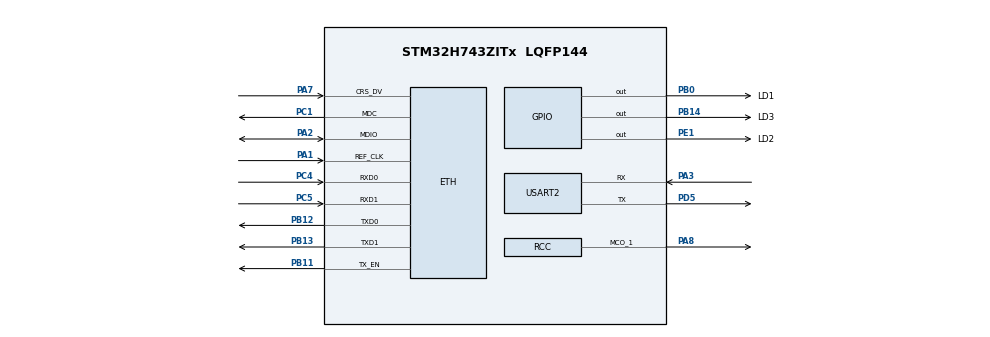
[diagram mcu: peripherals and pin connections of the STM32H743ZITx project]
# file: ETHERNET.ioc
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CORTEX_M7.CPU_DCache=Enabled
CORTEX_M7.CPU_ICache=Enabled
ETH.MediaInterface=HAL_ETH_RMII_MODE
LWIP.BSP.number=1
LWIP.GATEWAY_ADDRESS=192.168.001.001
LWIP.IP_ADDRESS=192.168.001.123
LWIP.LWIP_DHCP=0
LWIP.NETMASK_ADDRESS=255.255.255.000
LWIP.Version=v2.0.3_Cube
LWIP0.BSP.STBoard=false
LWIP0.BSP.api=BSP_COMPONENT_DRIVER
LWIP0.BSP.component=LAN8742
LWIP0.BSP.i2caddr=0
LWIP0.BSP.instance=LAN8742
LWIP0.BSP.name=Driver_PHY
LWIP0.BSP.solution=LAN8742
Mcu.Family=STM32H7
Mcu.Name=STM32H743ZITx
Mcu.Package=LQFP144
NVIC.ETH_IRQn=true\:0\:0\:false\:false\:true\:true\:true
NVIC.PriorityGroup=NVIC_PRIORITYGROUP_4
PA1.Mode=RMII
PA1.Signal=ETH_REF_CLK
PA2.Mode=RMII
PA2.Signal=ETH_MDIO
PA3.Mode=Asynchronous
PA3.Signal=USART2_RX
PA7.Mode=RMII
PA7.Signal=ETH_CRS_DV
PA8.Mode=Clock-out-1
PA8.Signal=RCC_MCO_1
PB0.GPIO_Label=LD1
PB0.GPIO_ModeDefaultOutputPP=GPIO_MODE_OUTPUT_PP
PB0.GPIO_PuPd=GPIO_NOPULL
PB0.GPIO_Speed=GPIO_SPEED_FREQ_VERY_HIGH
PB0.PinState=GPIO_PIN_RESET
PB0.Signal=GPIO_Output
PB11.Mode=RMII
PB11.Signal=ETH_TX_EN
PB12.Mode=RMII
PB12.Signal=ETH_TXD0
PB13.Mode=RMII
PB13.Signal=ETH_TXD1
PB14.GPIO_Label=LD3
PB14.GPIO_ModeDefaultOutputPP=GPIO_MODE_OUTPUT_PP
PB14.GPIO_PuPd=GPIO_NOPULL
PB14.GPIO_Speed=GPIO_SPEED_FREQ_VERY_HIGH
PB14.PinState=GPIO_PIN_RESET
PB14.Signal=GPIO_Output
PC1.Mode=RMII
PC1.Signal=ETH_MDC
PC4.Mode=RMII
PC4.Signal=ETH_RXD0
PC5.Mode=RMII
PC5.Signal=ETH_RXD1
PD5.Mode=Asynchronous
PD5.Signal=USART2_TX
PE1.GPIO_Label=LD2
PE1.GPIO_ModeDefaultOutputPP=GPIO_MODE_OUTPUT_PP
PE1.GPIO_PuPd=GPIO_NOPULL
PE1.GPIO_Speed=GPIO_SPEED_FREQ_VERY_HIGH
PE1.PinState=GPIO_PIN_RESET
PE1.Signal=GPIO_Output
PH0-OSC_IN\ (PH0).Mode=HSE-External-Oscillator
PH0-OSC_IN\ (PH0).Signal=RCC_OSC_IN
PH1-OSC_OUT\ (PH1).Mode=HSE-External-Oscillator
PH1-OSC_OUT\ (PH1).Signal=RCC_OSC_OUT
ProjectManager.HeapSize=0x200
ProjectManager.StackSize=0x400
ProjectManager.TargetToolchain=MDK-ARM V5.27
RCC.ADCFreq_Value=129000000
RCC.APB1Freq_Value=100000000
RCC.APB2Freq_Value=100000000
RCC.APB3Freq_Value=100000000
RCC.APB4Freq_Value=100000000
RCC.CortexFreq_Value=100000000
RCC.DIVM1=4
RCC.DIVN1=12
RCC.HCLKFreq_Value=100000000
RCC.PLL2FRACN=0
RCC.PLL3FRACN=0
RCC.PLLFRACN=4096
RCC.SYSCLKFreq_VALUE=100000000
RCC.SYSCLKSource=RCC_SYSCLKSOURCE_PLLCLK
RCC.USBFreq_Value=100000000
USART2.VirtualMode-Asynchronous=VM_ASYNC
VP_LWIP_VS_Enabled.Mode=Enabled
board=custom

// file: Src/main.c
/* USER CODE BEGIN Header */
/**
  ******************************************************************************
  * @file           : main.c
  * @brief          : Main program body
  ******************************************************************************
  * @attention
  *
  * <h2><center>&copy; Copyright (c) 2020 STMicroelectronics.
  * All rights reserved.</center></h2>
  *
  * This software component is licensed by ST under BSD 3-Clause license,
  * the "License"; You may not use this file except in compliance with the
  * License. You may obtain a copy of the License at:
  *                        opensource.org/licenses/BSD-3-Clause
  *
  ******************************************************************************
  */
/* USER CODE END Header */

#include "main.h"
#include "lwip.h"
#include "usart.h"
#include "gpio.h"

/* USER CODE BEGIN Includes */
#include <stdio.h>
/* USER CODE END Includes */

void SystemClock_Config(void);

/* USER CODE BEGIN 0 */
int fputc(int ch, FILE *f)
{
	HAL_UART_Transmit(&huart2, (uint8_t *)&ch, 1, 1000);
	ITM_SendChar(ch);
	return ch;
}
/* USER CODE END 0 */

int main(void)
{

  /* Enable I-Cache---------------------------------------------------------*/
  SCB_EnableICache();

  /* Enable D-Cache---------------------------------------------------------*/
  SCB_EnableDCache();

  /* MCU Configuration--------------------------------------------------------*/

  /* Reset of all peripherals, Initializes the Flash interface and the Systick. */
  HAL_Init();

  /* Configure the system clock */
  SystemClock_Config();

  /* Initialize all configured peripherals */
  MX_GPIO_Init();
  MX_USART2_UART_Init();
  MX_LWIP_Init();

  /* Infinite loop */
  while (1)
  {

    /* USER CODE BEGIN 3 */
		HAL_GPIO_TogglePin(LD1_GPIO_Port, LD1_Pin);
		HAL_GPIO_TogglePin(LD2_GPIO_Port, LD2_Pin);
		HAL_GPIO_TogglePin(LD3_GPIO_Port, LD3_Pin);
		printf("HelloWorld!!!\n");
		HAL_Delay(200);
  }
  /* USER CODE END 3 */
}

void SystemClock_Config(void)
{
  RCC_OscInitTypeDef RCC_OscInitStruct = {0};
  RCC_ClkInitTypeDef RCC_ClkInitStruct = {0};
  RCC_PeriphCLKInitTypeDef PeriphClkInitStruct = {0};

  /** Supply configuration update enable
  */
  HAL_PWREx_ConfigSupply(PWR_LDO_SUPPLY);
  /** Configure the main internal regulator output voltage
  */
  __HAL_PWR_VOLTAGESCALING_CONFIG(PWR_REGULATOR_VOLTAGE_SCALE3);

  while(!__HAL_PWR_GET_FLAG(PWR_FLAG_VOSRDY)) {}
  /** Initializes the CPU, AHB and APB busses clocks
  */
  RCC_OscInitStruct.OscillatorType = RCC_OSCILLATORTYPE_HSI;
  RCC_OscInitStruct.HSIState = RCC_HSI_DIV1;
  RCC_OscInitStruct.HSICalibrationValue = RCC_HSICALIBRATION_DEFAULT;
  RCC_OscInitStruct.PLL.PLLState = RCC_PLL_ON;
  RCC_OscInitStruct.PLL.PLLSource = RCC_PLLSOURCE_HSI;
  RCC_OscInitStruct.PLL.PLLM = 4;
  RCC_OscInitStruct.PLL.PLLN = 12;
  RCC_OscInitStruct.PLL.PLLP = 2;
  RCC_OscInitStruct.PLL.PLLQ = 2;
  RCC_OscInitStruct.PLL.PLLR = 2;
  RCC_OscInitStruct.PLL.PLLRGE = RCC_PLL1VCIRANGE_3;
  RCC_OscInitStruct.PLL.PLLVCOSEL = RCC_PLL1VCOWIDE;
  RCC_OscInitStruct.PLL.PLLFRACN = 4096;
  if (HAL_RCC_OscConfig(&RCC_OscInitStruct) != HAL_OK)
  {
    Error_Handler();
  }
  /** Initializes the CPU, AHB and APB busses clocks
  */
  RCC_ClkInitStruct.ClockType = RCC_CLOCKTYPE_HCLK|RCC_CLOCKTYPE_SYSCLK
                              |RCC_CLOCKTYPE_PCLK1|RCC_CLOCKTYPE_PCLK2
                              |RCC_CLOCKTYPE_D3PCLK1|RCC_CLOCKTYPE_D1PCLK1;
  RCC_ClkInitStruct.SYSCLKSource = RCC_SYSCLKSOURCE_PLLCLK;
  RCC_ClkInitStruct.SYSCLKDivider = RCC_SYSCLK_DIV1;
  RCC_ClkInitStruct.AHBCLKDivider = RCC_HCLK_DIV1;
  RCC_ClkInitStruct.APB3CLKDivider = RCC_APB3_DIV1;
  RCC_ClkInitStruct.APB1CLKDivider = RCC_APB1_DIV1;
  RCC_ClkInitStruct.APB2CLKDivider = RCC_APB2_DIV1;
  RCC_ClkInitStruct.APB4CLKDivider = RCC_APB4_DIV1;

  if (HAL_RCC_ClockConfig(&RCC_ClkInitStruct, FLASH_LATENCY_1) != HAL_OK)
  {
    Error_Handler();
  }
  PeriphClkInitStruct.PeriphClockSelection = RCC_PERIPHCLK_USART2;
  PeriphClkInitStruct.Usart234578ClockSelection = RCC_USART234578CLKSOURCE_D2PCLK1;
  if (HAL_RCCEx_PeriphCLKConfig(&PeriphClkInitStruct) != HAL_OK)
  {
    Error_Handler();
  }
  HAL_RCC_MCOConfig(RCC_MCO1, RCC_MCO1SOURCE_HSI, RCC_MCODIV_1);
}

void Error_Handler(void)
{
}

/************************ (C) COPYRIGHT STMicroelectronics *****END OF FILE****/
